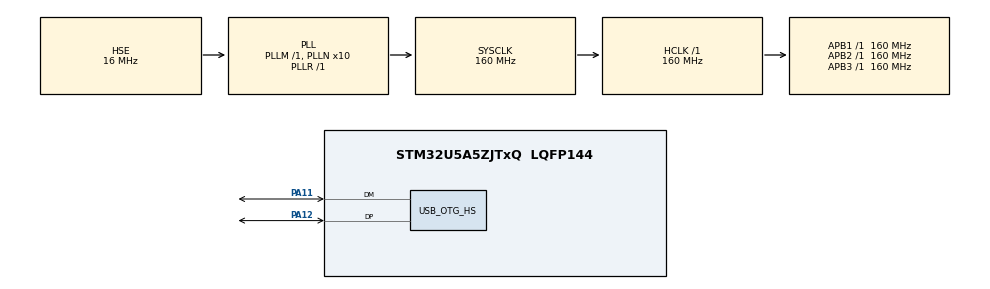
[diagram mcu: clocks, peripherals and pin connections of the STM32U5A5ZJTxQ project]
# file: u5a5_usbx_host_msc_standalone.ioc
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CORTEX_M33_NS.userName=CORTEX_M33
FILEX.FX_CUSTOM_INTERFACE=1
Mcu.Family=STM32U5
Mcu.Name=STM32U5A5ZJTxQ
Mcu.Package=LQFP144
NVIC.OTG_HS_IRQn=true\:0\:0\:false\:false\:true\:true\:true\:true
NVIC.PriorityGroup=NVIC_PRIORITYGROUP_4
PA11.Mode=Internal_Phy_Host
PA11.Signal=USB_OTG_HS_DM
PA12.Mode=Internal_Phy_Host
PA12.Signal=USB_OTG_HS_DP
PH0-OSC_IN\ (PH0).Mode=HSE-External-Oscillator
PH0-OSC_IN\ (PH0).Signal=RCC_OSC_IN
PH1-OSC_OUT\ (PH1).Mode=HSE-External-Oscillator
PH1-OSC_OUT\ (PH1).Signal=RCC_OSC_OUT
ProjectManager.HeapSize=0x200
ProjectManager.StackSize=0x400
ProjectManager.TargetToolchain=STM32CubeIDE
RCC.ADCFreq_Value=16000000
RCC.AHBFreq_Value=160000000
RCC.APB1Freq_Value=160000000
RCC.APB1TimFreq_Value=160000000
RCC.APB2Freq_Value=160000000
RCC.APB2TimFreq_Value=160000000
RCC.APB3Freq_Value=160000000
RCC.CortexFreq_Value=160000000
RCC.EPOD_VALUE=16000000
RCC.HCLKFreq_Value=160000000
RCC.HSE_VALUE=16000000
RCC.HSI48_VALUE=48000000
RCC.HSI_VALUE=16000000
RCC.LSE_VALUE=32768
RCC.LSIDIV_VALUE=32000
RCC.MSI_VALUE=4000000
RCC.PLL1R=1
RCC.PLLFRACN=0
RCC.PLLN=10
RCC.PLLSourceVirtual=RCC_PLLSOURCE_HSE
RCC.SYSCLKFreq_VALUE=160000000
RCC.SYSCLKSource=RCC_SYSCLKSOURCE_PLLCLK
RCC.USBPHYCLockSelection=RCC_USBPHYCLKSOURCE_HSE
RCC.VCOOutputFreq_Value=160000000
USBX.Core_System=1
USBX.USBX_HOST_SYS_SIZE=1024*9
USBX.UX_HOST_APP_MEM_POOL_SIZE_STANDALONE=1024*10
USBX.UX_Host_Controller=1
USBX.UX_Host_CoreStack=1
USBX.UX_Host_MSC=1
USB_OTG_HS.VirtualMode=Host_HS
VP_FILEX_VS_CustomOointerface.Mode=Custom_interface
VP_FILEX_VS_FileOoSystemJjFileXJjCore.Mode=FileX_Core
VP_LPBAMQUEUE_VS_QUEUE.Mode=QUEUEMODE
VP_LPBAM_VS_SIG1.Mode=SmartRun
VP_LPBAM_VS_SIG4.Mode=LPDMA1
VP_MEMORYMAP_VS_MEMORYMAP.Mode=CurAppReg
VP_PWR_VS_SECSignals.Mode=Security/Privilege
VP_USBX_Core_System.Mode=Core_System
VP_USBX_UX\ Host\ Controller_HS.Mode=UX_Host_Controller_HS
VP_USBX_UX\ Host\ CoreStack_HS.Mode=UX_Host_CoreStack_HS
VP_USBX_UX\ Host\ MSC_HS.Mode=UX_Host_MSC_HS
board=custom

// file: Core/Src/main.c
/* USER CODE BEGIN Header */
/**
  ******************************************************************************
  * @file           : main.c
  * @brief          : Main program body
  ******************************************************************************
  * @attention
  *
  * Copyright (c) 2025 STMicroelectronics.
  * All rights reserved.
  *
  * This software is licensed under terms that can be found in the LICENSE file
  * in the root directory of this software component.
  * If no LICENSE file comes with this software, it is provided AS-IS.
  *
  ******************************************************************************
  */
/* USER CODE END Header */
#include "main.h"
#include "app_filex.h"
#include "app_usbx_host.h"

/* USER CODE BEGIN Includes */
#include "ux_api.h"
#include "ux_host_class_storage.h"
#include "ux_hcd_stm32.h"
/* USER CODE END Includes */

HCD_HandleTypeDef hhcd_USB_OTG_HS;

/* USER CODE BEGIN PV */
UCHAR media_memory_buffer[4096] __attribute__((aligned(32)));

FX_MEDIA usb_disk;
extern UX_HOST_CLASS_STORAGE *storage;
extern UX_HOST_CLASS_STORAGE_MEDIA *storageMedia;
FX_MEDIA  *media;
extern uint32_t devConnected;
extern uint32_t mediaMounted;

uint8_t bufferRead[200];
uint32_t readBackCnt;
/* USER CODE END PV */

void SystemClock_Config(void);
static void MX_GPIO_Init(void);
static void MX_USB_OTG_HS_HCD_Init(void);

int main(void)
{

  /* MCU Configuration--------------------------------------------------------*/

  /* Reset of all peripherals, Initializes the Flash interface and the Systick. */
  HAL_Init();

  /* Configure the system clock */
  SystemClock_Config();

  /* Initialize all configured peripherals */
  MX_GPIO_Init();
  MX_FileX_Init();
  MX_USBX_Host_Init();
  /* USER CODE BEGIN 2 */
  MX_USB_OTG_HS_HCD_Init();
  /*connect usb peripery to usbx*/
  ux_host_stack_hcd_register(_ux_system_host_hcd_stm32_name,_ux_hcd_stm32_initialize, (ULONG)USB_OTG_HS,  (ULONG)&hhcd_USB_OTG_HS);
  /*start usb periphery*/
  HAL_HCD_Start(&hhcd_USB_OTG_HS);
  /* USER CODE END 2 */

  /* Infinite loop */
  /* USER CODE BEGIN WHILE */
  while (1)
  {
    ux_system_tasks_run();
    ux_host_stack_tasks_run();
    /* USER CODE END WHILE */

    /* USER CODE BEGIN 3 */

    if (devConnected && !mediaMounted && (storageMedia != UX_NULL) && (storage->ux_host_class_storage_state == UX_HOST_CLASS_INSTANCE_LIVE))
    {
      UINT status;
      status = fx_media_open(&usb_disk,
                              "USB_DISK",
                              fx_stm32_custom_driver,
                              storageMedia,
                              media_memory_buffer,
                              sizeof(media_memory_buffer));
      if (status == FX_SUCCESS)
      {
        mediaMounted = 1;
      }
    }
    if (mediaMounted)
    {
      FX_FILE file;
      UINT st = fx_file_open(&usb_disk, &file, "test.txt", FX_OPEN_FOR_READ);
      if (st == FX_SUCCESS)
      {
        st = fx_file_read(&file,bufferRead,200,&readBackCnt);

        fx_file_close(&file);
      }
    }
  }
  /* USER CODE END 3 */
}

void SystemClock_Config(void)
{
  RCC_OscInitTypeDef RCC_OscInitStruct = {0};
  RCC_ClkInitTypeDef RCC_ClkInitStruct = {0};

  /** Configure the main internal regulator output voltage
  */
  if (HAL_PWREx_ControlVoltageScaling(PWR_REGULATOR_VOLTAGE_SCALE1) != HAL_OK)
  {
    Error_Handler();
  }

  /** Initializes the CPU, AHB and APB buses clocks
  */
  RCC_OscInitStruct.OscillatorType = RCC_OSCILLATORTYPE_HSE;
  RCC_OscInitStruct.HSEState = RCC_HSE_ON;
  RCC_OscInitStruct.PLL.PLLState = RCC_PLL_ON;
  RCC_OscInitStruct.PLL.PLLSource = RCC_PLLSOURCE_HSE;
  RCC_OscInitStruct.PLL.PLLMBOOST = RCC_PLLMBOOST_DIV1;
  RCC_OscInitStruct.PLL.PLLM = 1;
  RCC_OscInitStruct.PLL.PLLN = 10;
  RCC_OscInitStruct.PLL.PLLP = 2;
  RCC_OscInitStruct.PLL.PLLQ = 2;
  RCC_OscInitStruct.PLL.PLLR = 1;
  RCC_OscInitStruct.PLL.PLLRGE = RCC_PLLVCIRANGE_1;
  RCC_OscInitStruct.PLL.PLLFRACN = 0;
  if (HAL_RCC_OscConfig(&RCC_OscInitStruct) != HAL_OK)
  {
    Error_Handler();
  }

  /** Initializes the CPU, AHB and APB buses clocks
  */
  RCC_ClkInitStruct.ClockType = RCC_CLOCKTYPE_HCLK|RCC_CLOCKTYPE_SYSCLK
                              |RCC_CLOCKTYPE_PCLK1|RCC_CLOCKTYPE_PCLK2
                              |RCC_CLOCKTYPE_PCLK3;
  RCC_ClkInitStruct.SYSCLKSource = RCC_SYSCLKSOURCE_PLLCLK;
  RCC_ClkInitStruct.AHBCLKDivider = RCC_SYSCLK_DIV1;
  RCC_ClkInitStruct.APB1CLKDivider = RCC_HCLK_DIV1;
  RCC_ClkInitStruct.APB2CLKDivider = RCC_HCLK_DIV1;
  RCC_ClkInitStruct.APB3CLKDivider = RCC_HCLK_DIV1;

  if (HAL_RCC_ClockConfig(&RCC_ClkInitStruct, FLASH_LATENCY_4) != HAL_OK)
  {
    Error_Handler();
  }
}

static void MX_USB_OTG_HS_HCD_Init(void)
{

  hhcd_USB_OTG_HS.Instance = USB_OTG_HS;
  hhcd_USB_OTG_HS.Init.Host_channels = 16;
  hhcd_USB_OTG_HS.Init.speed = HCD_SPEED_HIGH;
  hhcd_USB_OTG_HS.Init.dma_enable = DISABLE;
  hhcd_USB_OTG_HS.Init.phy_itface = USB_OTG_HS_EMBEDDED_PHY;
  hhcd_USB_OTG_HS.Init.Sof_enable = DISABLE;
  hhcd_USB_OTG_HS.Init.low_power_enable = DISABLE;
  hhcd_USB_OTG_HS.Init.use_external_vbus = ENABLE;
  if (HAL_HCD_Init(&hhcd_USB_OTG_HS) != HAL_OK)
  {
    Error_Handler();
  }

}

static void MX_GPIO_Init(void)
{

  /* GPIO Ports Clock Enable */
  __HAL_RCC_GPIOH_CLK_ENABLE();
  __HAL_RCC_GPIOA_CLK_ENABLE();

}

void Error_Handler(void)
{
  __disable_irq();
  while (1)
  {
  }
}
